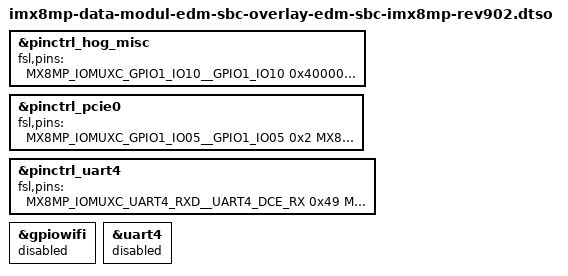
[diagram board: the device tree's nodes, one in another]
// SPDX-License-Identifier: (GPL-2.0+ OR MIT)
/*
 * Copyright (C) 2024-2026 Marek Vasut
 */
/dts-v1/;
/plugin/;

#include "imx8mp-pinfunc.h"

&pinctrl_hog_misc {
	fsl,pins = <
		/* ENET_WOL# -- shared by both PHYs */
		MX8MP_IOMUXC_GPIO1_IO10__GPIO1_IO10		0x40000090

		/* PG_V_IN_VAR# */
		MX8MP_IOMUXC_NAND_CE0_B__GPIO3_IO01		0x40000000
		/* CSI2_PD_1V8 */
		MX8MP_IOMUXC_NAND_DATA02__GPIO3_IO08		0x0
		/* CSI2_RESET_1V8# */
		MX8MP_IOMUXC_NAND_DATA03__GPIO3_IO09		0x0

		/* DIS_USB_DN1 */
		MX8MP_IOMUXC_SAI2_RXFS__GPIO4_IO21		0x0
		/* DIS_USB_DN2 */
		MX8MP_IOMUXC_SAI2_RXC__GPIO4_IO22		0x0

		/* EEPROM_WP_1V8# */
		MX8MP_IOMUXC_NAND_DQS__GPIO3_IO14		0x100
		/* PCIE_CLK_GEN_CLKPWRGD_PD_1V8# */
		MX8MP_IOMUXC_SAI5_RXD0__GPIO3_IO21		0x0
		/* GRAPHICS_PRSNT_1V8# */
		MX8MP_IOMUXC_SAI1_TXD6__GPIO4_IO18		0x40000000

		/* CLK_CCM_CLKO1_3V3 */
		MX8MP_IOMUXC_GPIO1_IO14__CCM_CLKO1		0x10
	>;
};

&pinctrl_pcie0 {
	fsl,pins = <
		/* M2_PCIE_RST# */
		MX8MP_IOMUXC_GPIO1_IO05__GPIO1_IO05		0x2
		/* M2_W_DISABLE1_1V8# */
		MX8MP_IOMUXC_SAI5_RXD2__GPIO3_IO23		0x2
		/* M2_W_DISABLE2_1V8# */
		MX8MP_IOMUXC_SAI5_RXD3__GPIO3_IO24		0x2
		/* CLK_M2_32K768 */
		MX8MP_IOMUXC_GPIO1_IO00__CCM_EXT_CLK1		0x14
		/* M2_PCIE_WAKE# */
		MX8MP_IOMUXC_GPIO1_IO06__GPIO1_IO06		0x40000140
		/* M2_PCIE_CLKREQ# */
		MX8MP_IOMUXC_I2C4_SCL__PCIE_CLKREQ_B		0x61
	>;
};

&pinctrl_uart4 {
	fsl,pins = <
		MX8MP_IOMUXC_UART4_RXD__UART4_DCE_RX		0x49
		MX8MP_IOMUXC_UART4_TXD__UART4_DCE_TX		0x49
	>;
};

&gpiowifi {
	status = "disabled";
};

&uart4 {
	status = "disabled";
};
